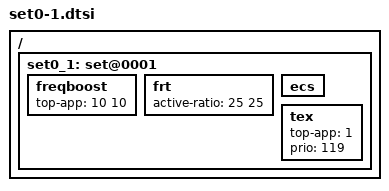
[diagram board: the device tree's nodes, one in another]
/ {
	/* normal mode - touch boost */
	set0_1: set@0001 {
		/* Boosting margin applied to frequency selection */
		freqboost {	   		/* LIT BIG */
			top-app         	= < 10  10>;
		};

		frt {	   			/* LIT BIG */
			active-ratio 		= < 25  25>;
		};

		ecs { };

		tex {
			top-app = <1>;
			prio = <119>;
		};
	};
};
